# CY8C5888LTI_LP097 register map
File version: 0.1
Registers are 8-bit, read-write, no defined reset value unless marked. A register's access mark holds for its fields unless they carry their own. Offsets are from the block's base; [hi:lo] are bit positions; 'fields as' and 'values as' point back to an identical list.

## Timer_L2
Base 0x00000000
0x40006409 Timer_L2_COUNTER 16-bit — UDB.A0 - Current Down Counter Value
0x40006429 Timer_L2_PERIOD 16-bit — UDB.D0 - Assigned Period
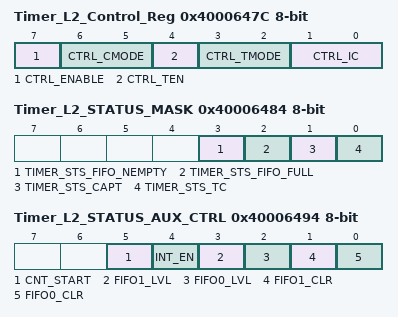
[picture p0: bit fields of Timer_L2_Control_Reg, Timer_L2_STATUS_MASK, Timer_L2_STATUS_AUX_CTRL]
0x4000647C Timer_L2_Control_Reg — UDB Control Register - Assigned Control Register Value
  [7] CTRL_ENABLE — Enable the Timer
  [6:5] CTRL_CMODE — Capture Mode
  [4] CTRL_TEN — Trigger Enable Bit
  [3:2] CTRL_TMODE — Trigger Mode
  [1:0] CTRL_IC — Interrupt Count
0x40006484 Timer_L2_STATUS_MASK — UDB Status bits Interrupt Mask Enable Register
  [3] TIMER_STS_FIFO_NEMPTY ro — FIFO Empty status
  [2] TIMER_STS_FIFO_FULL ro — FIFO Full Status
  [1] TIMER_STS_CAPT ro — Enables the Interrupt on Capture
  [0] TIMER_STS_TC ro — Enables the Interrupt on TC
0x40006494 Timer_L2_STATUS_AUX_CTRL — UDB Auxilliary Control Register
  [5] CNT_START — FIFO0 clear
    0=E_CNT_START0 (Disable counter); 1=E_CNT_START1 (Enable counter)
  [4] INT_EN
    0=E_INT_EN0 (Interrupt disabled); 1=E_INT_EN1 (Interrupt enabled)
  [3] FIFO1_LVL — FIFO level
    0=E_FIFO_LVL_0 (FIFO LVL: input mode: FIFO not full; output mode: FIFO not empty); 1=E_FIFO_LVL_1 (FIFO LVL: input mode: FIFO at least 1/2 empty; output mode: FIFO at least 1/2 full)
  [2] FIFO0_LVL — FIFO level
    values as FIFO1_LVL
  [1] FIFO1_CLR — FIFO1 clear
    0=E_FIFO_CLR_0 (Normal FIFO operation); 1=E_FIFO_CLR_1 (Clear FIFO state)
  [0] FIFO0_CLR — FIFO0 clear
    values as FIFO1_CLR

## Timer_IR
Base 0x00000000
0x40006406 Timer_IR_COUNTER 24-bit — UDB.A0 - Current Down Counter Value
0x40006426 Timer_IR_PERIOD 24-bit — UDB.D0 - Assigned Period
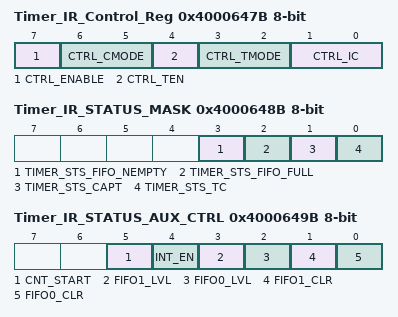
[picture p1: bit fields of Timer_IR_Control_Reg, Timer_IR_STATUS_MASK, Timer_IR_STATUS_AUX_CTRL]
0x4000647B Timer_IR_Control_Reg — UDB Control Register - Assigned Control Register Value
  [7] CTRL_ENABLE — Enable the Timer
  [6:5] CTRL_CMODE — Capture Mode
  [4] CTRL_TEN — Trigger Enable Bit
  [3:2] CTRL_TMODE — Trigger Mode
  [1:0] CTRL_IC — Interrupt Count
0x4000648B Timer_IR_STATUS_MASK — UDB Status bits Interrupt Mask Enable Register
  [3] TIMER_STS_FIFO_NEMPTY ro — FIFO Empty status
  [2] TIMER_STS_FIFO_FULL ro — FIFO Full Status
  [1] TIMER_STS_CAPT ro — Enables the Interrupt on Capture
  [0] TIMER_STS_TC ro — Enables the Interrupt on TC
0x4000649B Timer_IR_STATUS_AUX_CTRL — UDB Auxilliary Control Register
  [5] CNT_START — FIFO0 clear
    0=E_CNT_START0 (Disable counter); 1=E_CNT_START1 (Enable counter)
  [4] INT_EN
    0=E_INT_EN0 (Interrupt disabled); 1=E_INT_EN1 (Interrupt enabled)
  [3] FIFO1_LVL — FIFO level
    0=E_FIFO_LVL_0 (FIFO LVL: input mode: FIFO not full; output mode: FIFO not empty); 1=E_FIFO_LVL_1 (FIFO LVL: input mode: FIFO at least 1/2 empty; output mode: FIFO at least 1/2 full)
  [2] FIFO0_LVL — FIFO level
    values as FIFO1_LVL
  [1] FIFO1_CLR — FIFO1 clear
    0=E_FIFO_CLR_0 (Normal FIFO operation); 1=E_FIFO_CLR_1 (Clear FIFO state)
  [0] FIFO0_CLR — FIFO0 clear
    values as FIFO1_CLR

## StatisticsCounter
Base 0x00000000
0x40006402 StatisticsCounter_COUNTER 32-bit — UDB.A0 - Current Counter Value
0x40006422 StatisticsCounter_PERIOD 32-bit — UDB.D0 - Assigned Period
0x40006432 StatisticsCounter_COMPARE 32-bit — UDB.D1 - Assigned Compare Value
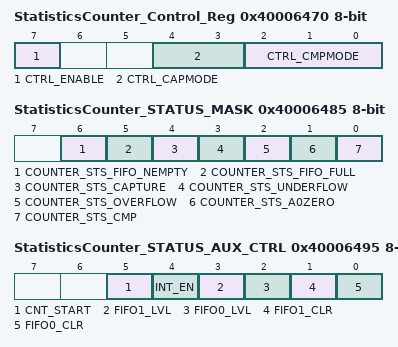
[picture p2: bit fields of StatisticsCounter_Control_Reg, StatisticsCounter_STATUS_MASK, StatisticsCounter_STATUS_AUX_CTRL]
0x40006470 StatisticsCounter_Control_Reg — UDB Control Register - Assigned Control Register Value
  [7] CTRL_ENABLE — Enable Counter
  [4:3] CTRL_CAPMODE — Capture mode
  [2:0] CTRL_CMPMODE — Compare mode
0x40006485 StatisticsCounter_STATUS_MASK — UDB Status bits Interrupt Mask Enable Register
  [6] COUNTER_STS_FIFO_NEMPTY — FIFO Not Empty Status
  [5] COUNTER_STS_FIFO_FULL — FIFO Full Status
  [4] COUNTER_STS_CAPTURE — Capture Status
  [3] COUNTER_STS_UNDERFLOW — Underflow status
  [2] COUNTER_STS_OVERFLOW — Overflow status
  [1] COUNTER_STS_A0ZERO — A0 Zero ouput status
  [0] COUNTER_STS_CMP — Compare output status
0x40006495 StatisticsCounter_STATUS_AUX_CTRL — UDB Auxilliary Control Register
  [5] CNT_START — FIFO0 clear
    0=E_CNT_START0 (Disable counter); 1=E_CNT_START1 (Enable counter)
  [4] INT_EN
    0=E_INT_EN0 (Interrupt disabled); 1=E_INT_EN1 (Interrupt enabled)
  [3] FIFO1_LVL — FIFO level
    0=E_FIFO_LVL_0 (FIFO LVL: input mode: FIFO not full; output mode: FIFO not empty); 1=E_FIFO_LVL_1 (FIFO LVL: input mode: FIFO at least 1/2 empty; output mode: FIFO at least 1/2 full)
  [2] FIFO0_LVL — FIFO level
    values as FIFO1_LVL
  [1] FIFO1_CLR — FIFO1 clear
    0=E_FIFO_CLR_0 (Normal FIFO operation); 1=E_FIFO_CLR_1 (Clear FIFO state)
  [0] FIFO0_CLR — FIFO0 clear
    values as FIFO1_CLR
